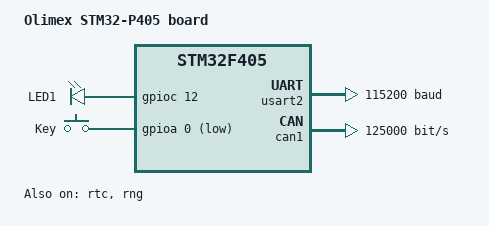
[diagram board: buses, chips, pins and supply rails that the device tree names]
/*
 * Copyright (c) 2017, Erwin Rol <erwin@erwinrol.com>
 *
 * SPDX-License-Identifier: Apache-2.0
 */

/dts-v1/;
#include <st/f4/stm32f405Xg.dtsi>

/ {
	model = "Olimex STM32-P405 board";
	compatible = "olimex,stm32-p405", "st,stm32f405";

	chosen {
		zephyr,console = &usart2;
		zephyr,shell-uart = &usart2;
		zephyr,sram = &sram0;
		zephyr,flash = &flash0;
		zephyr,ccm = &ccm0;
		zephyr,can-primary = &can1;
	};

	leds {
		compatible = "gpio-leds";
		green_led_1: led_1 {
			gpios = <&gpioc 12 GPIO_ACTIVE_HIGH>;
			label = "LED1";
		};
	};

	gpio_keys {
		compatible = "gpio-keys";
		user_button: button {
			label = "Key";
			gpios = <&gpioa 0 GPIO_ACTIVE_LOW>;
		};
	};

	aliases {
		led0 = &green_led_1;
		sw0 = &user_button;
	};
};

&usart2 {
	current-speed = <115200>;
	status = "okay";
};

&rtc {
	status = "okay";
};

&can1 {
	bus-speed = <125000>;
	status = "okay";
};

&rng {
	status = "okay";
};
